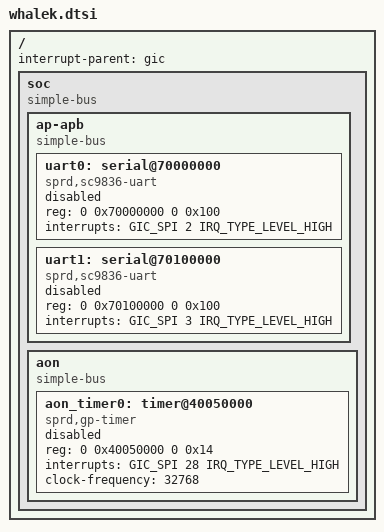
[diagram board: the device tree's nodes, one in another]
/*
 * Spreadtrum Whalek platform DTS file
 *
 * Copyright (C) 2016, Spreadtrum Communications Inc.
 *
 * This file is licensed under a dual GPLv2 or X11 license.
 */

#include <dt-bindings/interrupt-controller/arm-gic.h>

/ {
	interrupt-parent = <&gic>;
	#address-cells = <2>;
	#size-cells = <2>;

	soc: soc {
		compatible = "simple-bus";
		#address-cells = <2>;
		#size-cells = <2>;
		ranges;


		ap-apb {
			compatible = "simple-bus";
			#address-cells = <2>;
			#size-cells = <2>;
			ranges;

			uart0: serial@70000000 {
				compatible = "sprd,sc9836-uart",
					     "sprd,sc9838-uart";
				reg = <0 0x70000000 0 0x100>;
				interrupts = <GIC_SPI 2 IRQ_TYPE_LEVEL_HIGH>;
				status = "disabled";
			};

			uart1: serial@70100000 {
				compatible = "sprd,sc9836-uart",
					     "sprd,sc9838-uart";
				reg = <0 0x70100000 0 0x100>;
				interrupts = <GIC_SPI 3 IRQ_TYPE_LEVEL_HIGH>;
				status = "disabled";
			};
		};

		aon {
			compatible = "simple-bus";
			#address-cells = <2>;
			#size-cells = <2>;
			ranges;

			aon_timer0: timer@40050000 {
				compatible = "sprd,gp-timer";
				reg = <0 0x40050000 0 0x14>;
				interrupts = <GIC_SPI 28 IRQ_TYPE_LEVEL_HIGH>;
				clock-frequency = <32768>;
				status = "disable";
			};
		};

	};
};

